# EFR32MG22C224F512IM40 register map
Vendor: Silicon Labs; Series: EFR32; File version: F
Registers are 32-bit, read-write, reset 0x0 unless marked. A register's access mark holds for its fields unless they carry their own. Offsets are from the block's base; [hi:lo] are bit positions; 'fields as' and 'values as' point back to an identical list.

## DCDC_NS — DCDC_NS Registers
Base 0x50094000
Same registers: DCDC_S 0x40094000
0x00 IPVERSION ro
0x04 EN — Enable
  [0] EN
    0=DISABLE; 1=ENABLE
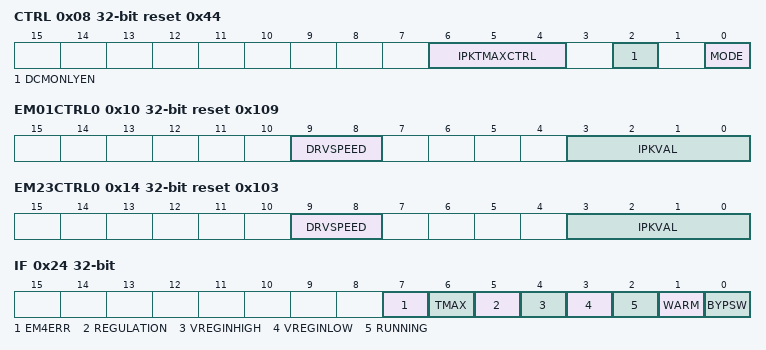
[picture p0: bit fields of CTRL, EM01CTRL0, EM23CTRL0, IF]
0x08 CTRL reset 0x44 — Control
  [6:4] IPKTMAXCTRL — Peak Current Timeout Control
    0=OFF (Ton_max disabled); 1=TMAX_0P35us (0.35us); 2=TMAX_0P63us (0.63us); 3=TMAX_0P91us (0.91us); 4=TMAX_1P19us (1.19us); 5=TMAX_1P47us (1.47us); 6=TMAX_1P75us (1.75us); 7=TMAX_2P03us (2.03us)
  [2] DCMONLYEN — DCDC DCM Only Enable
    0=DUALMODE (Support higher load current at lower battery voltage by working in CCM mode); 1=DCMONLYEN (DCM only mode for normal operation, this is the default setting)
  [0] MODE — DCDC/Bypass Mode Control
    0=BYPASS (DCDC is OFF, bypass switch is enabled); 1=DCDCREGULATION (Request DCDC regulation, bypass switch disabled)
0x10 EM01CTRL0 reset 0x109 — EM01 Configurations
  [9:8] DRVSPEED — EM01 Drive Speed Setting
    0=BEST_EMI (Not recommended for use (no benefit to this setting)); 1=DEFAULT_SETTING (Recommended for use for best efficiency and low EMI); 2=INTERMEDIATE (Not recommended for use (no benefit to this setting)); 3=BEST_EFFICIENCY (Not recommended for use (no benefit to this setting))
  [3:0] IPKVAL — EM01 Peak Current Setting
    3=Load36mA (Ipeak = 90mA, Iload = 36mA); 4=Load40mA (Ipeak = 100mA, Iload = 40mA); 5=Load44mA (Ipeak = 110mA, Iload = 44mA); 6=Load48mA (Ipeak = 120mA, Iload = 48mA); 7=Load52mA (Ipeak = 130mA, Iload = 52mA); 8=Load56mA (Ipeak = 140mA, Iload = 56mA); 9=Load60mA (Ipeak = 150mA, Iload = 60mA)
0x14 EM23CTRL0 reset 0x103 — EM23 Configurations
  [9:8] DRVSPEED — EM23 Drive Speed Setting
    values as EM01CTRL0.DRVSPEED
  [3:0] IPKVAL — EM23 Peak Current Setting
    3=LOAD5MA (Ipeak = 90mA, Iload = 5 mA); 9=LOAD10MA (Ipeak = 150mA, Iload = 10 mA)
0x24 IF — Interrupt Flags
  [7] EM4ERR — EM4 Entry Request Error
  [6] TMAX — Ton_max Timeout Reached
  [5] REGULATION — DCDC in regulation
  [4] VREGINHIGH — VREGVDD above threshold
  [3] VREGINLOW — VREGVDD below threshold
  [2] RUNNING — DCDC Running
  [1] WARM — DCDC Warmup Time Done
  [0] BYPSW — Bypass Switch Enabled
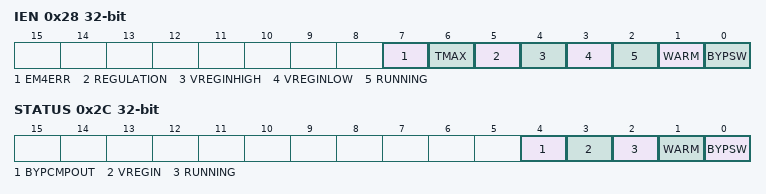
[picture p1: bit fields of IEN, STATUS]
0x28 IEN — Interrupt Enable
  [7] EM4ERR — EM4 Entry Req Interrupt Enable
  [6] TMAX — Ton_max Timeout Interrupt Enable
  [5] REGULATION — DCDC in Regulation Interrupt Enable
  [4] VREGINHIGH — VREGVDD above threshold Interrupt Enable
  [3] VREGINLOW — VREGVDD below threshold Interrupt Enable
  [2] RUNNING — DCDC Running Interrupt Enable
  [1] WARM — DCDC Warmup Time Done Interrupt Enable
  [0] BYPSW — Bypass Switch Enabled Interrupt Enable
0x2C STATUS ro — DCDC Status Register
  [4] BYPCMPOUT — Bypass Comparator Output
  [3] VREGIN — VREGVDD comparator status
  [2] RUNNING — DCDC is running
  [1] WARM — DCDC Warmup Done
  [0] BYPSW — Bypass Switch is currently enabled
0x40 LOCK wo
  [15:0] LOCKKEY — Configuration Lock Key
    0xABCD=UNLOCKKEY (Value to write to unlock)
0x44 LOCKSTATUS ro
  [0] LOCK — Lock Status
    0=UNLOCKED (Unlocked State); 1=LOCKED (LOCKED STATE)

## DPLL0_NS — DPLL0_NS Registers
Base 0x5001C000
Same registers: DPLL0_S 0x4001C000
0x00 IPVERSION ro
  [31:0] IPVERSION — IP Version ID
0x04 EN
  [0] EN — Module Enable
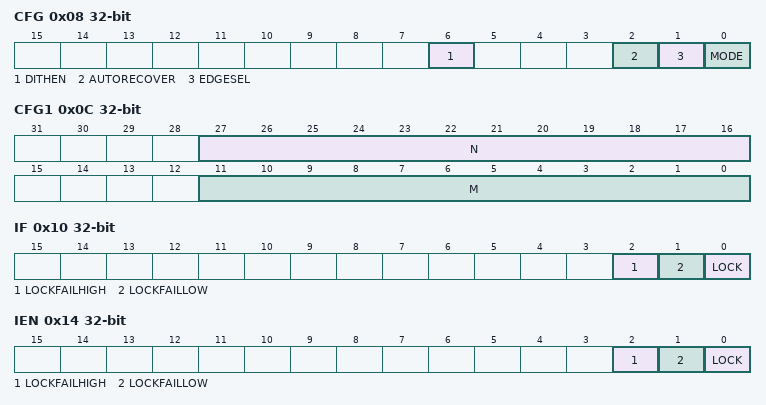
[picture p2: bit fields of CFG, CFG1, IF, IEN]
0x08 CFG
  [6] DITHEN — Dither Enable Control
  [2] AUTORECOVER — Automatic Recovery Control
  [1] EDGESEL — Reference Edge Select
  [0] MODE — Operating Mode Control
    0=FLL (Frequency Lock Mode); 1=PLL (Phase Lock Mode)
0x0C CFG1
  [27:16] N — Factor N
  [11:0] M — Factor M
0x10 IF
  [2] LOCKFAILHIGH — Lock Failure High Interrupt Flag
  [1] LOCKFAILLOW — Lock Failure Low Interrupt Flag
  [0] LOCK — Lock Interrupt Flag
0x14 IEN
  [2] LOCKFAILHIGH — LOCKFAILHIGH Interrupt Enable
  [1] LOCKFAILLOW — LOCKFAILLOW Interrupe Enable
  [0] LOCK — LOCK interrupt Enable
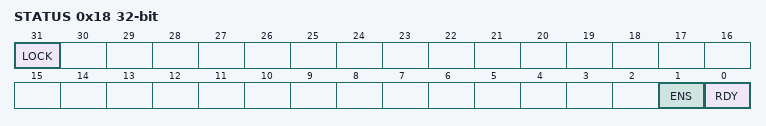
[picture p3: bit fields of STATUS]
0x18 STATUS ro
  [31] LOCK — Lock Status
    0=UNLOCKED (DPLL is unlocked); 1=LOCKED (DPLL is locked)
  [1] ENS — Enable Status
  [0] RDY — Ready Status
0x24 LOCK wo reset 0x7102
  [15:0] LOCKKEY
    0x7102=UNLOCK (Unlock code)
